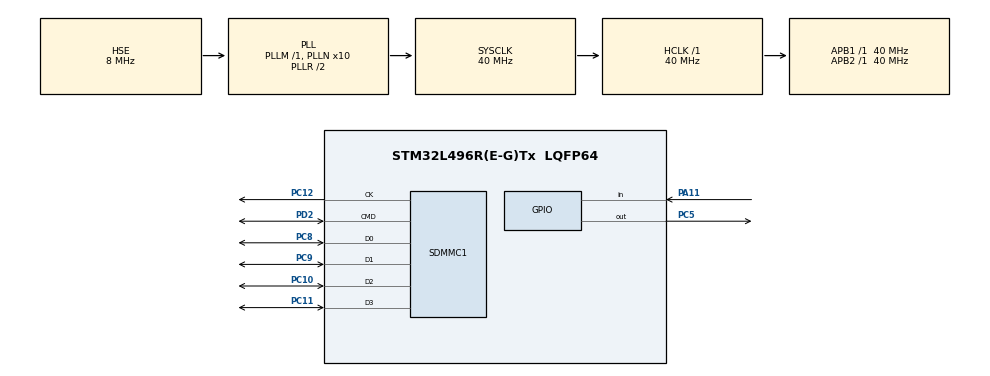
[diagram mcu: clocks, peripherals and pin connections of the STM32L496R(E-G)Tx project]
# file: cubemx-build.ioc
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Dma.Request0=SDMMC1_RX
Dma.Request1=SDMMC1_TX
Dma.SDMMC1_RX.0.Direction=DMA_PERIPH_TO_MEMORY
Dma.SDMMC1_RX.0.Instance=DMA2_Channel4
Dma.SDMMC1_RX.0.MemDataAlignment=DMA_MDATAALIGN_WORD
Dma.SDMMC1_RX.0.MemInc=DMA_MINC_ENABLE
Dma.SDMMC1_RX.0.Mode=DMA_NORMAL
Dma.SDMMC1_RX.0.PeriphDataAlignment=DMA_PDATAALIGN_WORD
Dma.SDMMC1_RX.0.PeriphInc=DMA_PINC_DISABLE
Dma.SDMMC1_RX.0.Priority=DMA_PRIORITY_LOW
Dma.SDMMC1_TX.1.Direction=DMA_MEMORY_TO_PERIPH
Dma.SDMMC1_TX.1.Instance=DMA2_Channel5
Dma.SDMMC1_TX.1.MemDataAlignment=DMA_MDATAALIGN_WORD
Dma.SDMMC1_TX.1.MemInc=DMA_MINC_ENABLE
Dma.SDMMC1_TX.1.Mode=DMA_NORMAL
Dma.SDMMC1_TX.1.PeriphDataAlignment=DMA_PDATAALIGN_WORD
Dma.SDMMC1_TX.1.PeriphInc=DMA_PINC_DISABLE
Dma.SDMMC1_TX.1.Priority=DMA_PRIORITY_LOW
FATFS.BSP.number=1
FATFS._FS_EXFAT=1
FATFS._USE_LFN=2
FATFS0.BSP.STBoard=false
FATFS0.BSP.api=Unknown
FATFS0.BSP.i2caddr=0
FATFS0.BSP.instance=PA11
FATFS0.BSP.ip=GPIO
FATFS0.BSP.mode=Input
FATFS0.BSP.name=Detect_SDIO
FATFS0.BSP.solution=PA11
Mcu.Family=STM32L4
Mcu.Name=STM32L496R(E-G)Tx
Mcu.Package=LQFP64
NVIC.DMA2_Channel4_IRQn=true\:0\:0\:false\:false\:true\:false\:true\:true
NVIC.DMA2_Channel5_IRQn=true\:0\:0\:false\:false\:true\:false\:true\:true
NVIC.PriorityGroup=NVIC_PRIORITYGROUP_4
PA11.GPIO_PuPd=GPIO_PULLDOWN
PA11.Signal=GPIO_Input
PA13\ (JTMS/SWDIO).Mode=Serial_Wire
PA13\ (JTMS/SWDIO).Signal=SYS_JTMS-SWDIO
PA14\ (JTCK/SWCLK).Mode=Serial_Wire
PA14\ (JTCK/SWCLK).Signal=SYS_JTCK-SWCLK
PC10.Mode=SD_4_bits_Wide_bus
PC10.Signal=SDMMC1_D2
PC11.Mode=SD_4_bits_Wide_bus
PC11.Signal=SDMMC1_D3
PC12.Mode=SD_4_bits_Wide_bus
PC12.Signal=SDMMC1_CK
PC5.Signal=GPIO_Output
PC8.Mode=SD_4_bits_Wide_bus
PC8.Signal=SDMMC1_D0
PC9.Mode=SD_4_bits_Wide_bus
PC9.Signal=SDMMC1_D1
PD2.Mode=SD_4_bits_Wide_bus
PD2.Signal=SDMMC1_CMD
PH0-OSC_IN\ (PH0).Mode=HSE-External-Oscillator
PH0-OSC_IN\ (PH0).Signal=RCC_OSC_IN
PH1-OSC_OUT\ (PH1).Mode=HSE-External-Oscillator
PH1-OSC_OUT\ (PH1).Signal=RCC_OSC_OUT
ProjectManager.HeapSize=0x200
ProjectManager.StackSize=0x400
ProjectManager.TargetToolchain=Makefile
RCC.ADCFreq_Value=32000000
RCC.AHBFreq_Value=40000000
RCC.APB1Freq_Value=40000000
RCC.APB1TimFreq_Value=40000000
RCC.APB2Freq_Value=40000000
RCC.APB2TimFreq_Value=40000000
RCC.CortexFreq_Value=40000000
RCC.HCLKFreq_Value=40000000
RCC.HSE_VALUE=8000000
RCC.HSI48_VALUE=48000000
RCC.HSI_VALUE=16000000
RCC.LSE_VALUE=32768
RCC.MSI_VALUE=4000000
RCC.PLLN=10
RCC.PLLSourceVirtual=RCC_PLLSOURCE_HSE
RCC.SYSCLKFreq_VALUE=40000000
RCC.SYSCLKSource=RCC_SYSCLKSOURCE_PLLCLK
RCC.USBFreq_Value=32000000
RCC.VCOOutputFreq_Value=80000000
SDMMC1.ClockPowerSave=SDMMC_CLOCK_POWER_SAVE_ENABLE
VP_FATFS_VS_SDIO.Mode=SDIO
board=custom

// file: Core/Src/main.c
/* USER CODE BEGIN Header */
/**
  ******************************************************************************
  * @file           : main.c
  * @brief          : Main program body
  ******************************************************************************
  * @attention
  *
  * Copyright (c) 2022 STMicroelectronics.
  * All rights reserved.
  *
  * This software is licensed under terms that can be found in the LICENSE file
  * in the root directory of this software component.
  * If no LICENSE file comes with this software, it is provided AS-IS.
  *
  ******************************************************************************
  */
/* USER CODE END Header */
#include "main.h"
#include "dma.h"
#include "fatfs.h"
#include "sdmmc.h"
#include "gpio.h"

/* USER CODE BEGIN Includes */

#include "string.h"
#include "deadbeef.h"

/* USER CODE END Includes */

/* USER CODE BEGIN PV */

FRESULT fres;
FATFS fs = { 0 };
FATFS *pfs;
UINT byteswritten;
UINT bytesread;
BYTE work[4096];
FIL fil;
DWORD fre_clust;
uint32_t total, totalfree;
static const uint8_t deadbeef[][16] = DEADBEEF;

/* USER CODE END PV */

void SystemClock_Config(void);

int main(void)
{

  /* MCU Configuration--------------------------------------------------------*/

  /* Reset of all peripherals, Initializes the Flash interface and the Systick. */
  HAL_Init();

  /* Configure the system clock */
  SystemClock_Config();

  /* Initialize all configured peripherals */
  MX_GPIO_Init();
  MX_SDMMC1_SD_Init();
  MX_DMA_Init();
  MX_FATFS_Init();
  /* USER CODE BEGIN 2 */

  fres = f_open(&fil, "test.txt", FA_CREATE_ALWAYS | FA_WRITE);
  //fres = f_write(&fil, &asdf, 16 * 1, &byteswritten);
  fres = f_write(&fil, &deadbeef, 8 * 1, &byteswritten);

  /* USER CODE END 2 */

  /* Infinite loop */
  while (1)
  {

  }
}

void SystemClock_Config(void)
{
  RCC_OscInitTypeDef RCC_OscInitStruct = {0};
  RCC_ClkInitTypeDef RCC_ClkInitStruct = {0};

  /** Configure the main internal regulator output voltage
  */
  if (HAL_PWREx_ControlVoltageScaling(PWR_REGULATOR_VOLTAGE_SCALE1) != HAL_OK)
  {
    Error_Handler();
  }

  /** Initializes the RCC Oscillators according to the specified parameters
  * in the RCC_OscInitTypeDef structure.
  */
  RCC_OscInitStruct.OscillatorType = RCC_OSCILLATORTYPE_HSE;
  RCC_OscInitStruct.HSEState = RCC_HSE_ON;
  RCC_OscInitStruct.PLL.PLLState = RCC_PLL_ON;
  RCC_OscInitStruct.PLL.PLLSource = RCC_PLLSOURCE_HSE;
  RCC_OscInitStruct.PLL.PLLM = 1;
  RCC_OscInitStruct.PLL.PLLN = 10;
  RCC_OscInitStruct.PLL.PLLP = RCC_PLLP_DIV2;
  RCC_OscInitStruct.PLL.PLLQ = RCC_PLLQ_DIV2;
  RCC_OscInitStruct.PLL.PLLR = RCC_PLLR_DIV2;
  if (HAL_RCC_OscConfig(&RCC_OscInitStruct) != HAL_OK)
  {
    Error_Handler();
  }

  /** Initializes the CPU, AHB and APB buses clocks
  */
  RCC_ClkInitStruct.ClockType = RCC_CLOCKTYPE_HCLK|RCC_CLOCKTYPE_SYSCLK
                              |RCC_CLOCKTYPE_PCLK1|RCC_CLOCKTYPE_PCLK2;
  RCC_ClkInitStruct.SYSCLKSource = RCC_SYSCLKSOURCE_PLLCLK;
  RCC_ClkInitStruct.AHBCLKDivider = RCC_SYSCLK_DIV1;
  RCC_ClkInitStruct.APB1CLKDivider = RCC_HCLK_DIV1;
  RCC_ClkInitStruct.APB2CLKDivider = RCC_HCLK_DIV1;

  if (HAL_RCC_ClockConfig(&RCC_ClkInitStruct, FLASH_LATENCY_2) != HAL_OK)
  {
    Error_Handler();
  }
}

void Error_Handler(void)
{
  __disable_irq();
  while (1)
  {
  }
}
